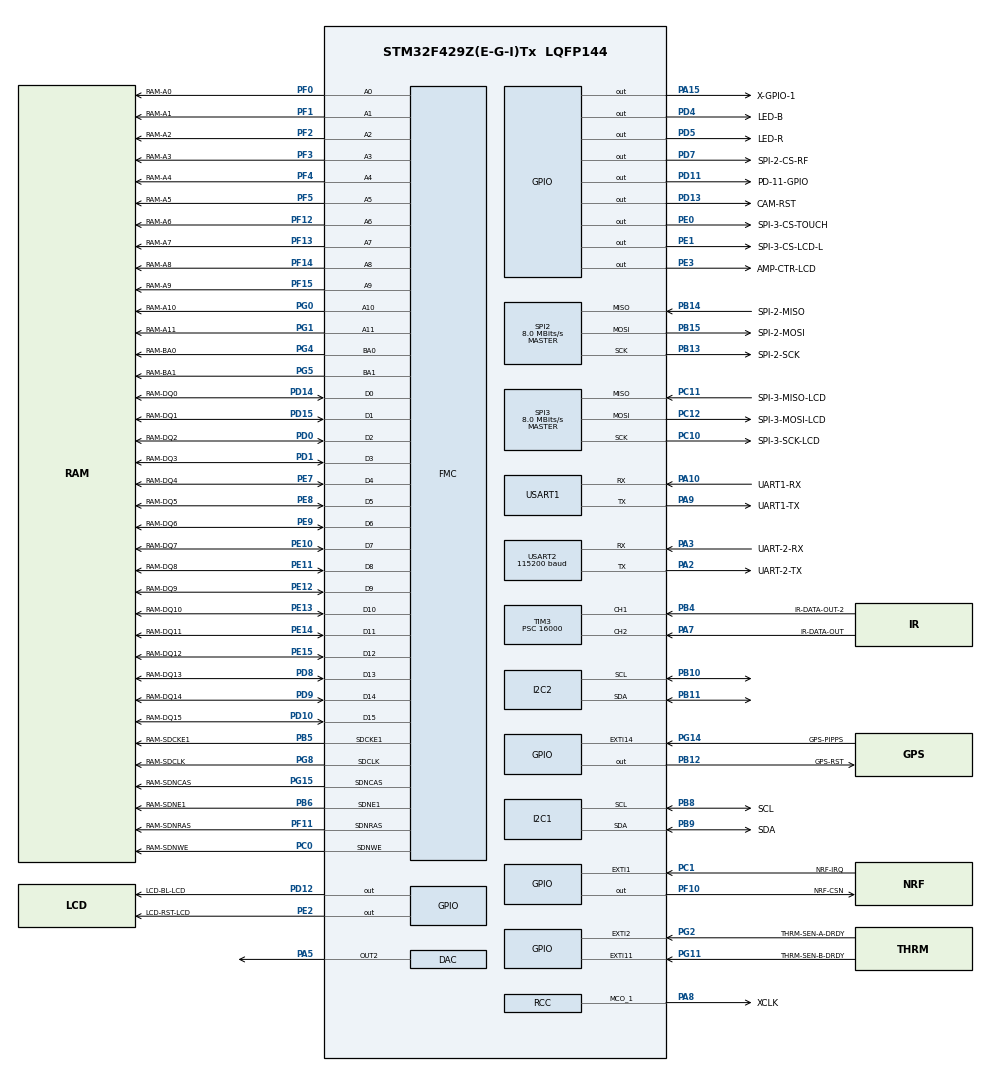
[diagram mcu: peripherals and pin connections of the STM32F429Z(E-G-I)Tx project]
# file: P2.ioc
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DAC.DAC_OutputBuffer2=DAC_OUTPUTBUFFER_ENABLE
DAC.DAC_Trigger2=DAC_TRIGGER_T6_TRGO
DAC.TriangleAmplitude2=DAC_TRIANGLEAMPLITUDE_4095
DAC.WaveGeneration2=TriangleWaveGeneration
Dma.I2C1_RX.2.Channel=DMA_CHANNEL_1
Dma.I2C1_RX.2.Direction=DMA_PERIPH_TO_MEMORY
Dma.I2C1_RX.2.FIFOMode=DMA_FIFOMODE_DISABLE
Dma.I2C1_RX.2.Instance=DMA1_Stream0
Dma.I2C1_RX.2.MemDataAlignment=DMA_MDATAALIGN_BYTE
Dma.I2C1_RX.2.MemInc=DMA_MINC_ENABLE
Dma.I2C1_RX.2.Mode=DMA_NORMAL
Dma.I2C1_RX.2.PeriphDataAlignment=DMA_PDATAALIGN_BYTE
Dma.I2C1_RX.2.PeriphInc=DMA_PINC_DISABLE
Dma.I2C1_RX.2.Priority=DMA_PRIORITY_LOW
Dma.Request0=SPI2_RX
Dma.Request1=SPI2_TX
Dma.Request2=I2C1_RX
Dma.Request3=USART2_RX
Dma.SPI2_RX.0.Channel=DMA_CHANNEL_0
Dma.SPI2_RX.0.Direction=DMA_PERIPH_TO_MEMORY
Dma.SPI2_RX.0.FIFOMode=DMA_FIFOMODE_DISABLE
Dma.SPI2_RX.0.Instance=DMA1_Stream3
Dma.SPI2_RX.0.MemDataAlignment=DMA_MDATAALIGN_BYTE
Dma.SPI2_RX.0.MemInc=DMA_MINC_ENABLE
Dma.SPI2_RX.0.Mode=DMA_NORMAL
Dma.SPI2_RX.0.PeriphDataAlignment=DMA_PDATAALIGN_BYTE
Dma.SPI2_RX.0.PeriphInc=DMA_PINC_DISABLE
Dma.SPI2_RX.0.Priority=DMA_PRIORITY_LOW
Dma.SPI2_TX.1.Channel=DMA_CHANNEL_0
Dma.SPI2_TX.1.Direction=DMA_MEMORY_TO_PERIPH
Dma.SPI2_TX.1.FIFOMode=DMA_FIFOMODE_DISABLE
Dma.SPI2_TX.1.Instance=DMA1_Stream4
Dma.SPI2_TX.1.MemDataAlignment=DMA_MDATAALIGN_BYTE
Dma.SPI2_TX.1.MemInc=DMA_MINC_ENABLE
Dma.SPI2_TX.1.Mode=DMA_NORMAL
Dma.SPI2_TX.1.PeriphDataAlignment=DMA_PDATAALIGN_BYTE
Dma.SPI2_TX.1.PeriphInc=DMA_PINC_DISABLE
Dma.SPI2_TX.1.Priority=DMA_PRIORITY_LOW
Dma.USART2_RX.3.Channel=DMA_CHANNEL_4
Dma.USART2_RX.3.Direction=DMA_PERIPH_TO_MEMORY
Dma.USART2_RX.3.FIFOMode=DMA_FIFOMODE_DISABLE
Dma.USART2_RX.3.Instance=DMA1_Stream5
Dma.USART2_RX.3.MemDataAlignment=DMA_MDATAALIGN_BYTE
Dma.USART2_RX.3.MemInc=DMA_MINC_ENABLE
Dma.USART2_RX.3.Mode=DMA_NORMAL
Dma.USART2_RX.3.PeriphDataAlignment=DMA_PDATAALIGN_BYTE
Dma.USART2_RX.3.PeriphInc=DMA_PINC_DISABLE
Dma.USART2_RX.3.Priority=DMA_PRIORITY_LOW
I2C1.NoStretchMode=I2C_NOSTRETCH_DISABLED
Mcu.Family=STM32F4
Mcu.Name=STM32F429Z(E-G-I)Tx
Mcu.Package=LQFP144
NVIC.DMA1_Stream0_IRQn=true\:0\:0\:false
NVIC.DMA1_Stream3_IRQn=true\:0\:0\:false
NVIC.DMA1_Stream4_IRQn=true\:0\:0\:false
NVIC.DMA1_Stream5_IRQn=true\:0\:0\:false
NVIC.EXTI15_10_IRQn=true\:0\:0\:false
NVIC.EXTI1_IRQn=true\:0\:0\:false
NVIC.EXTI2_IRQn=true\:0\:0\:false
NVIC.PriorityGroup=NVIC_PRIORITYGROUP_4
NVIC.RCC_IRQn=true\:0\:0\:false
NVIC.TIM3_IRQn=true\:0\:0\:false
NVIC.USART1_IRQn=true\:0\:0\:false
PA10.GPIO_Label=UART1-RX
PA10.Mode=Asynchronous
PA10.Signal=USART1_RX
PA13.Mode=Serial-Wire
PA13.Signal=SYS_JTMS-SWDIO
PA14.Mode=Serial-Wire
PA14.Signal=SYS_JTCK-SWCLK
PA15.GPIO_Label=X-GPIO-1
PA15.GPIO_PuPd=GPIO_PULLDOWN
PA15.Signal=GPIO_Output
PA2.GPIO_Label=UART-2-TX
PA2.GPIO_Speed=GPIO_SPEED_LOW
PA2.Mode=Asynchronous
PA2.Signal=USART2_TX
PA3.GPIO_Label=UART-2-RX
PA3.GPIO_Speed=GPIO_SPEED_LOW
PA3.Mode=Asynchronous
PA3.Signal=USART2_RX
PA5.Signal=COMP_DAC2_group
PA7.GPIO_Label=IR-DATA-OUT
PA7.Signal=S_TIM3_CH2
PA8.GPIO_Label=XCLK
PA8.GPIO_PuPd=GPIO_NOPULL
PA8.GPIO_Speed=GPIO_SPEED_FAST
PA8.Mode=Clock-out-1
PA8.Signal=RCC_MCO_1
PA9.GPIO_Label=UART1-TX
PA9.Mode=Asynchronous
PA9.Signal=USART1_TX
PB10.GPIO_PuPdOD=GPIO_NOPULL
PB10.GPIO_Speed=GPIO_SPEED_FAST
PB10.Mode=I2C
PB10.Signal=I2C2_SCL
PB11.GPIO_PuPdOD=GPIO_NOPULL
PB11.GPIO_Speed=GPIO_SPEED_FAST
PB11.Mode=I2C
PB11.Signal=I2C2_SDA
PB12.GPIO_Label=GPS-RST
PB12.Signal=GPIO_Output
PB13.GPIO_Label=SPI-2-SCK
PB13.Mode=Full_Duplex_Master
PB13.Signal=SPI2_SCK
PB14.GPIO_Label=SPI-2-MISO
PB14.Mode=Full_Duplex_Master
PB14.Signal=SPI2_MISO
PB15.GPIO_Label=SPI-2-MOSI
PB15.Mode=Full_Duplex_Master
PB15.Signal=SPI2_MOSI
PB4.GPIO_Label=IR-DATA-OUT-2
PB4.Signal=S_TIM3_CH1
PB5.GPIO_Label=RAM-SDCKE1
PB5.Mode=SdramChipSelect2_1
PB5.Signal=FMC_SDCKE1
PB6.GPIO_Label=RAM-SDNE1
PB6.Mode=SdramChipSelect2_1
PB6.Signal=FMC_SDNE1
PB8.GPIO_Label=SCL
PB8.GPIO_PuPdOD=GPIO_PULLUP
PB8.GPIO_Speed=GPIO_SPEED_MEDIUM
PB8.Mode=I2C
PB8.Signal=I2C1_SCL
PB9.GPIO_Label=SDA
PB9.GPIO_PuPdOD=GPIO_PULLUP
PB9.GPIO_Speed=GPIO_SPEED_MEDIUM
PB9.Mode=I2C
PB9.Signal=I2C1_SDA
PC0.GPIO_Label=RAM-SDNWE
PC0.Signal=FMC_SDNWE
PC1.GPIO_Label=NRF-IRQ
PC1.GPIO_ModeDefaultEXTI=GPIO_MODE_IT_FALLING
PC1.Signal=GPXTI1
PC10.GPIO_Label=SPI-3-SCK-LCD
PC10.GPIO_Speed=GPIO_SPEED_MEDIUM
PC10.Mode=Full_Duplex_Master
PC10.Signal=SPI3_SCK
PC11.GPIO_Label=SPI-3-MISO-LCD
PC11.GPIO_Speed=GPIO_SPEED_MEDIUM
PC11.Mode=Full_Duplex_Master
PC11.Signal=SPI3_MISO
PC12.GPIO_Label=SPI-3-MOSI-LCD
PC12.GPIO_Speed=GPIO_SPEED_MEDIUM
PC12.Mode=Full_Duplex_Master
PC12.Signal=SPI3_MOSI
PC14/OSC32_IN.Mode=LSE-External-Oscillator
PC14/OSC32_IN.Signal=RCC_OSC32_IN
PC15/OSC32_OUT.Mode=LSE-External-Oscillator
PC15/OSC32_OUT.Signal=RCC_OSC32_OUT
PD0.GPIO_Label=RAM-DQ2
PD0.Signal=FMC_D2_DA2
PD1.GPIO_Label=RAM-DQ3
PD1.Signal=FMC_D3_DA3
PD10.GPIO_Label=RAM-DQ15
PD10.Signal=FMC_D15_DA15
PD11.GPIO_Label=PD-11-GPIO
PD11.Signal=GPIO_Output
PD12.GPIO_Label=LCD-BL-LCD
PD12.Signal=GPIO_Output
PD13.GPIO_Label=CAM-RST
PD13.GPIO_PuPd=GPIO_PULLDOWN
PD13.GPIO_Speed=GPIO_SPEED_LOW
PD13.Signal=GPIO_Output
PD14.GPIO_Label=RAM-DQ0
PD14.Signal=FMC_D0_DA0
PD15.GPIO_Label=RAM-DQ1
PD15.Signal=FMC_D1_DA1
PD4.GPIO_Label=LED-B
PD4.Signal=GPIO_Output
PD5.GPIO_Label=LED-R
PD5.Signal=GPIO_Output
PD7.GPIO_Label=SPI-2-CS-RF
PD7.Signal=GPIO_Output
PD8.GPIO_Label=RAM-DQ13
PD8.Signal=FMC_D13_DA13
PD9.GPIO_Label=RAM-DQ14
PD9.Signal=FMC_D14_DA14
PE0.GPIO_Label=SPI-3-CS-TOUCH
PE0.GPIO_ModeDefaultOutputPP=GPIO_MODE_OUTPUT_PP
PE0.GPIO_PuPd=GPIO_NOPULL
PE0.Signal=GPIO_Output
PE1.GPIO_Label=SPI-3-CS-LCD-L
PE1.GPIO_ModeDefaultOutputPP=GPIO_MODE_OUTPUT_PP
PE1.GPIO_PuPd=GPIO_NOPULL
PE1.GPIO_Speed=GPIO_SPEED_LOW
PE1.Signal=GPIO_Output
PE10.GPIO_Label=RAM-DQ7
PE10.Signal=FMC_D7_DA7
PE11.GPIO_Label=RAM-DQ8
PE11.Signal=FMC_D8_DA8
PE12.GPIO_Label=RAM-DQ9
PE12.Signal=FMC_D9_DA9
PE13.GPIO_Label=RAM-DQ10
PE13.Signal=FMC_D10_DA10
PE14.GPIO_Label=RAM-DQ11
PE14.Signal=FMC_D11_DA11
PE15.GPIO_Label=RAM-DQ12
PE15.Signal=FMC_D12_DA12
PE2.GPIO_Label=LCD-RST-LCD
PE2.GPIO_ModeDefaultOutputPP=GPIO_MODE_OUTPUT_PP
PE2.GPIO_PuPd=GPIO_NOPULL
PE2.Signal=GPIO_Output
PE3.GPIO_Label=AMP-CTR-LCD
PE3.GPIO_ModeDefaultOutputPP=GPIO_MODE_OUTPUT_OD
PE3.GPIO_PuPd=GPIO_NOPULL
PE3.Signal=GPIO_Output
PE7.GPIO_Label=RAM-DQ4
PE7.Signal=FMC_D4_DA4
PE8.GPIO_Label=RAM-DQ5
PE8.Signal=FMC_D5_DA5
PE9.GPIO_Label=RAM-DQ6
PE9.Signal=FMC_D6_DA6
PF0.GPIO_Label=RAM-A0
PF0.Signal=FMC_A0
PF1.GPIO_Label=RAM-A1
PF1.Signal=FMC_A1
PF10.GPIO_Label=NRF-CSN
PF10.GPIO_ModeDefaultOutputPP=GPIO_MODE_OUTPUT_PP
PF10.GPIO_PuPd=GPIO_NOPULL
PF10.Signal=GPIO_Output
PF11.GPIO_Label=RAM-SDNRAS
PF11.Signal=FMC_SDNRAS
PF12.GPIO_Label=RAM-A6
PF12.Signal=FMC_A6
PF13.GPIO_Label=RAM-A7
PF13.Signal=FMC_A7
PF14.GPIO_Label=RAM-A8
PF14.Signal=FMC_A8
PF15.GPIO_Label=RAM-A9
PF15.Signal=FMC_A9
PF2.GPIO_Label=RAM-A2
PF2.Signal=FMC_A2
PF3.GPIO_Label=RAM-A3
PF3.Signal=FMC_A3
PF4.GPIO_Label=RAM-A4
PF4.Signal=FMC_A4
PF5.GPIO_Label=RAM-A5
PF5.Signal=FMC_A5
PG0.GPIO_Label=RAM-A10
PG0.Signal=FMC_A10
PG1.GPIO_Label=RAM-A11
PG1.Signal=FMC_A11
PG11.GPIO_Label=THRM-SEN-B-DRDY
PG11.GPIO_ModeDefaultEXTI=GPIO_MODE_IT_RISING
PG11.GPIO_PuPd=GPIO_NOPULL
PG11.Signal=GPXTI11
PG14.GPIO_Label=GPS-PIPPS
PG14.GPIO_PuPd=GPIO_NOPULL
PG14.Signal=GPXTI14
PG15.GPIO_Label=RAM-SDNCAS
PG15.Signal=FMC_SDNCAS
PG2.GPIO_Label=THRM-SEN-A-DRDY
PG2.GPIO_ModeDefaultEXTI=GPIO_MODE_IT_RISING
PG2.GPIO_PuPd=GPIO_NOPULL
PG2.Signal=GPXTI2
PG4.GPIO_Label=RAM-BA0
PG4.Signal=FMC_A14_BA0
PG5.GPIO_Label=RAM-BA1
PG5.Signal=FMC_A15_BA1
PG8.GPIO_Label=RAM-SDCLK
PG8.Signal=FMC_SDCLK
PH0/OSC_IN.Mode=HSE-External-Oscillator
PH0/OSC_IN.Signal=RCC_OSC_IN
PH1/OSC_OUT.Mode=HSE-External-Oscillator
PH1/OSC_OUT.Signal=RCC_OSC_OUT
ProjectManager.TargetToolchain=MDK-ARM V5
RCC.48MHZClocksFreq_Value=16000000
RCC.AHBFreq_Value=16000000
RCC.APB1Freq_Value=16000000
RCC.APB1TimFreq_Value=16000000
RCC.APB2Freq_Value=16000000
RCC.APB2TimFreq_Value=16000000
RCC.CortexFreq_Value=16000000
RCC.HCLKFreq_Value=16000000
RCC.HSE_VALUE=25000000
RCC.HSICalibrationValue=0
RCC.HSI_VALUE=16000000
RCC.PLLM=59
RCC.PLLN=236
RCC.RCC_TIM_PRescaler_Selection=RCC_TIMPRES_DESACTIVATED
RCC.SYSCLKFreq_VALUE=16000000
RCC.VCOOutputFreq_Value=64000000
SH.COMP_DAC2_group.0=DAC_OUT2,DAC_OUT2
SH.FMC_A0.0=FMC_A0,12b-sda1
SH.FMC_A1.0=FMC_A1,12b-sda1
SH.FMC_A10.0=FMC_A10,12b-sda1
SH.FMC_A11.0=FMC_A11,12b-sda1
SH.FMC_A14_BA0.0=FMC_BA0,FourSdramBanks1
SH.FMC_A15_BA1.0=FMC_BA1,FourSdramBanks1
SH.FMC_A2.0=FMC_A2,12b-sda1
SH.FMC_A3.0=FMC_A3,12b-sda1
SH.FMC_A4.0=FMC_A4,12b-sda1
SH.FMC_A5.0=FMC_A5,12b-sda1
SH.FMC_A6.0=FMC_A6,12b-sda1
SH.FMC_A7.0=FMC_A7,12b-sda1
SH.FMC_A8.0=FMC_A8,12b-sda1
SH.FMC_A9.0=FMC_A9,12b-sda1
SH.FMC_D0_DA0.0=FMC_D0,sd-16b-d1
SH.FMC_D10_DA10.0=FMC_D10,sd-16b-d1
SH.FMC_D11_DA11.0=FMC_D11,sd-16b-d1
SH.FMC_D12_DA12.0=FMC_D12,sd-16b-d1
SH.FMC_D13_DA13.0=FMC_D13,sd-16b-d1
SH.FMC_D14_DA14.0=FMC_D14,sd-16b-d1
SH.FMC_D15_DA15.0=FMC_D15,sd-16b-d1
SH.FMC_D1_DA1.0=FMC_D1,sd-16b-d1
SH.FMC_D2_DA2.0=FMC_D2,sd-16b-d1
SH.FMC_D3_DA3.0=FMC_D3,sd-16b-d1
SH.FMC_D4_DA4.0=FMC_D4,sd-16b-d1
SH.FMC_D5_DA5.0=FMC_D5,sd-16b-d1
SH.FMC_D6_DA6.0=FMC_D6,sd-16b-d1
SH.FMC_D7_DA7.0=FMC_D7,sd-16b-d1
SH.FMC_D8_DA8.0=FMC_D8,sd-16b-d1
SH.FMC_D9_DA9.0=FMC_D9,sd-16b-d1
SH.FMC_SDCLK.0=FMC_SDCLK,12b-sda1
SH.FMC_SDNCAS.0=FMC_SDNCAS,12b-sda1
SH.FMC_SDNRAS.0=FMC_SDNRAS,12b-sda1
SH.FMC_SDNWE.0=FMC_SDNWE,12b-sda1
SH.S_TIM3_CH1.0=TIM3_CH1,Input_Capture1_from_TI1
SH.S_TIM3_CH1.1=TIM3_CH1,TriggerSource_TI1FP1
SH.S_TIM3_CH2.0=TIM3_CH2,Input_Capture2_from_TI2
SPI2.CalculateBaudRate=8.0 MBits/s
SPI2.Mode=SPI_MODE_MASTER
SPI3.BaudRatePrescaler=SPI_BAUDRATEPRESCALER_2
SPI3.CLKPolarity=SPI_POLARITY_LOW
SPI3.CalculateBaudRate=8.0 MBits/s
SPI3.DataSize=SPI_DATASIZE_8BIT
SPI3.Mode=SPI_MODE_MASTER
TIM3.Channel-Input_Capture2_from_TI2=TIM_CHANNEL_2
TIM3.ICPolarity_CH1=TIM_INPUTCHANNELPOLARITY_RISING
TIM3.Period=19
TIM3.Prescaler=16000
TIM3.TIM_MasterOutputTrigger=TIM_TRGO_UPDATE
TIM6.Period=5
TIM6.Prescaler=0
TIM6.TIM_MasterOutputTrigger=TIM_TRGO_UPDATE
USART2.BaudRate=115200
USART2.WordLength=UART_WORDLENGTH_8B
VP_TIM3_VS_ClockSourceINT.Mode=Internal
VP_TIM3_VS_ControllerModeReset.Mode=Reset Mode
VP_TIM6_VS_ClockSourceINT.Mode=Enable_Timer
board=P2

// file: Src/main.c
/**
  ******************************************************************************
  * File Name          : main.c
  * Description        : Main program body
  ******************************************************************************
  *
  * COPYRIGHT(c) 2015 STMicroelectronics
  *
  * Redistribution and use in source and binary forms, with or without modification,
  * are permitted provided that the following conditions are met:
  *   1. Redistributions of source code must retain the above copyright notice,
  *      this list of conditions and the following disclaimer.
  *   2. Redistributions in binary form must reproduce the above copyright notice,
  *      this list of conditions and the following disclaimer in the documentation
  *      and/or other materials provided with the distribution.
  *   3. Neither the name of STMicroelectronics nor the names of its contributors
  *      may be used to endorse or promote products derived from this software
  *      without specific prior written permission.
  *
  * THIS SOFTWARE IS PROVIDED BY THE COPYRIGHT HOLDERS AND CONTRIBUTORS "AS IS"
  * AND ANY EXPRESS OR IMPLIED WARRANTIES, INCLUDING, BUT NOT LIMITED TO, THE
  * IMPLIED WARRANTIES OF MERCHANTABILITY AND FITNESS FOR A PARTICULAR PURPOSE ARE
  * DISCLAIMED. IN NO EVENT SHALL THE COPYRIGHT HOLDER OR CONTRIBUTORS BE LIABLE
  * FOR ANY DIRECT, INDIRECT, INCIDENTAL, SPECIAL, EXEMPLARY, OR CONSEQUENTIAL
  * DAMAGES (INCLUDING, BUT NOT LIMITED TO, PROCUREMENT OF SUBSTITUTE GOODS OR
  * SERVICES; LOSS OF USE, DATA, OR PROFITS; OR BUSINESS INTERRUPTION) HOWEVER
  * CAUSED AND ON ANY THEORY OF LIABILITY, WHETHER IN CONTRACT, STRICT LIABILITY,
  * OR TORT (INCLUDING NEGLIGENCE OR OTHERWISE) ARISING IN ANY WAY OUT OF THE USE
  * OF THIS SOFTWARE, EVEN IF ADVISED OF THE POSSIBILITY OF SUCH DAMAGE.
  *
  ******************************************************************************
  */
#include "stm32f4xx_hal.h"

/* USER CODE BEGIN Includes */
//#include "stdio.h"
//#include "3_I2C1_TMP006.h"
//#include "4_5_I2C1_Si7020.h"
//#include "8_UART1.h"
//#include "10_SPI2_NRF24L01.h"
//#include "12_FMC_SDRAM.h"
#include "15_lights.h"
//#include "19_UART2_GPS.h"
//#include "18_I2C1_MPU9150.h"
//#include "17_DAC_Audio.h"
//#include "14_IR_Sensor.h"
struct __FILE { int handle; };
FILE __stdout;
FILE __stdin;
int fputc(int c, FILE *f)
{
ITM_SendChar(c);
return (c);
}

//#include "SPI3_LCD.h"
//#include "7_I2C2_OV7670.h"

/* USER CODE END Includes */

DAC_HandleTypeDef hdac;

I2C_HandleTypeDef hi2c1;
I2C_HandleTypeDef hi2c2;
DMA_HandleTypeDef hdma_i2c1_rx;

SPI_HandleTypeDef hspi2;
SPI_HandleTypeDef hspi3;
DMA_HandleTypeDef hdma_spi2_rx;
DMA_HandleTypeDef hdma_spi2_tx;

TIM_HandleTypeDef htim3;
TIM_HandleTypeDef htim6;

UART_HandleTypeDef huart1;
UART_HandleTypeDef huart2;
DMA_HandleTypeDef hdma_usart2_rx;

SDRAM_HandleTypeDef hsdram1;

/* USER CODE BEGIN PV */
/* Private variables ---------------------------------------------------------*/

uint16_t  si_eid1 = 0;
uint16_t  si_eid2 = 0;
uint8_t  si_firm = 0;
uint8_t  si_heat = 0;
float    si_hum = 0;
float    si_temp = 0 ;
float    si_temp_r = 0 ;

uint8_t cam_pid_msb = 0;
uint8_t cam_pid_lsb = 0;
uint8_t cam_gain = 0;
uint8_t cam_blue = 0;
uint8_t cam_red = 0;

uint16_t tmp006_dev_id1 = 0;
uint16_t tmp006_man_id1 = 0;
uint16_t tmp006_temp1 = 0;
uint16_t tmp006_sens1 = 0;

uint16_t tmp006_dev_id2 = 0;
uint16_t tmp006_man_id2 = 0;
uint16_t tmp006_temp2 = 0;
uint16_t tmp006_sens2 = 0;

uint8_t nrf_config = 0;
uint8_t nrf_en_aa = 0;
uint8_t nrf_en_rxaddr = 0;
uint8_t nrf_setup_aw = 0;
uint8_t nrf_setup_retr = 0;
uint8_t nrf_rf_ch = 0;
uint8_t nrf_rf_setup = 0;
uint8_t nrf_status = 0;
uint8_t nrf_observe_tx  = 0;

uint8_t gps_sid = 0;

uint64_t lcd_man_id =0;
uint64_t lcd_dri_ver = 0;
uint64_t lcd_dri_id = 0;
uint64_t lcd_mem_acc_con = 0;
uint64_t lcd_disp_pow_mod = 0;
uint64_t lcd_rddsdr = 0;
uint64_t lcd_disp_stat = 0;
uint64_t lcd_mem_read = 0;

uint8_t   acc_smprt_div = 0;
uint8_t   acc_config = 0;
uint8_t   acc_gyro_config = 0;
uint16_t  ACCEL_XOUT_H = 0;
uint8_t   ACCEL_XOUT_L = 0;
uint16_t  ACCEL_YOUT_H = 0;
uint8_t   ACCEL_YOUT_L = 0;
uint16_t  ACCEL_ZOUT_H = 0;
uint8_t   ACCEL_ZOUT_L = 0;
uint16_t  GYRO_XOUT_H  = 0;
uint8_t   GYRO_XOUT_L  = 0;
uint16_t  GYRO_YOUT_H  = 0;
uint8_t   GYRO_YOUT_L  = 0;
uint16_t  GYRO_ZOUT_H  = 0;
uint8_t   GYRO_ZOUT_L  = 0;

uint8_t  acc_who_am_i = 0;
uint8_t  acc_pwr_mgmt_1;
uint8_t  acc_pwr_mgmt_2;

uint32_t DAC_Out = 0 ;

extern uint32_t sd_rb;       // READ BUFFER FOR SD CARD

/* USER CODE END PV */

void SystemClock_Config(void);
static void MX_GPIO_Init(void);
static void MX_DMA_Init(void);
static void MX_DAC_Init(void);
static void MX_FMC_Init(void);
static void MX_I2C1_Init(void);
static void MX_I2C2_Init(void);
static void MX_SPI2_Init(void);
static void MX_SPI3_Init(void);
static void MX_TIM3_Init(void);
static void MX_TIM6_Init(void);
static void MX_USART1_UART_Init(void);
static void MX_USART2_UART_Init(void);

/* USER CODE BEGIN PFP */
/* Private function prototypes -----------------------------------------------*/

/* USER CODE END PFP */

int main(void)
{

  /* MCU Configuration----------------------------------------------------------*/

  /* Reset of all peripherals, Initializes the Flash interface and the Systick. */
  HAL_Init();

  /* Configure the system clock */
  SystemClock_Config();

  /* Initialize all configured peripherals */
  MX_GPIO_Init();
  MX_DMA_Init();
  MX_DAC_Init();
  MX_FMC_Init();
  MX_I2C1_Init();
  MX_I2C2_Init();
  MX_SPI2_Init();
  MX_SPI3_Init();
  MX_TIM3_Init();
  MX_TIM6_Init();
  MX_USART1_UART_Init();
  MX_USART2_UART_Init();

  /* USER CODE BEGIN 2 */

	 // TMP006 FUNCTIONS

	/***********************************/

	tmp006_man_id1 = r_man_id1();
	tmp006_dev_id1 = r_dev_id1();
	tmp006_man_id2 = r_man_id2();
	tmp006_dev_id2 = r_dev_id2();
	tmp006_temp1 = r_temp1();
	tmp006_sens1 = r_sens1();
  tmp006_temp2 = r_temp2();
	tmp006_sens2 = r_sens2();

	/**************************************/

/*************** NRF2401L  FUNCTIONS *****************

w_config(0x04);
nrf_config     = r_config();    // READ CONFIGURATION REGISTER OF NRF24L01
nrf_en_aa      = r_en_aa();     // READ ENABLE AUTO ACKNOWLEDGEMENT REGISTER OF NRF24L01
nrf_en_rxaddr  = r_en_rxaddr(); // READ ENABLED RX ADDRESSES OF NRF24L01
nrf_setup_aw   = r_setup_aw();  // READ SETUP OF ADDRESS WIDTHS OF NRF24L01
nrf_setup_retr = r_setup_retr();// READ SETUP OF AUTOMATIC RETRANSMISSION REGISTER OF NRF24L01
nrf_rf_ch      = r_rf_ch();     // READ RF CHANNEL REGISTER OF NRF24L01
nrf_rf_setup   = r_rf_setup() ; // READ RF SETUP REGISTER OF NRF24L01
nrf_status     = r_status();    // READ STATUS REGISTER OF NRF24L01
nrf_observe_tx = r_observe_tx();// READ TRANSMIT OBSERVE REGISTER OF NRF24L01
r_rpd        ();                // READ RECEIVED POWER DETECT REGISTER OF NRF24L01
r_rx_addr_p0 ();                // READ RECEIVED DATA PIPE 0
r_rx_addr_p1 ();                // READ RECEIVED DATA PIPE 1
r_rx_addr_p2 ();                // READ RECEIVED DATA PIPE 2
r_rx_addr_p3 ();                // READ RECEIVED DATA PIPE 3
r_rx_addr_p4 ();                // READ RECEIVED DATA PIPE 4
r_rx_addr_p5 ();                // READ RECEIVED DATA PIPE 5
r_tx_addr    ();                // READ RECEIVED TRANSMIT REGISTER OF NRF24L01
r_rx_pw_p0   ();                // READ NUMBER OF BYTES IN RX PAYLOAD IN DATA PIPE 0 OF NRF24L01
r_rx_pw_p1   ();                // READ NUMBER OF BYTES IN RX PAYLOAD IN DATA PIPE 1 OF NRF24L01
r_rx_pw_p2   ();                // READ NUMBER OF BYTES IN RX PAYLOAD IN DATA PIPE 2 OF NRF24L01
r_rx_pw_p3   ();                // READ NUMBER OF BYTES IN RX PAYLOAD IN DATA PIPE 3 OF NRF24L01
r_rx_pw_p4   ();                // READ NUMBER OF BYTES IN RX PAYLOAD IN DATA PIPE 4 OF NRF24L01
r_rx_pw_p5   ();                // READ NUMBER OF BYTES IN RX PAYLOAD IN DATA PIPE 5 OF NRF24L01

************************************************************************************************/

/********** SDRAM FUNCTIONS******************

uint32_t data[] = {0x0A,0x0B,0x0C,0x0D};
write_sd_mem((uint32_t*)data);
read_sd_mem();

*******************************************/

/*************UART SERIAL CAMERA INTERFACE*******************

uint8_t buff[] ="hello";
uart1_send((uint8_t*)buff);

**********************************************************/

/*************ACCELROMETER/GYROSCOPE FUNCTIONS***********

mpu_stat();
acc_who_am_i     =  r_who_am_i();
slp_mod_of();
w_smprt_div(0x18);
acc_smprt_div    =  r_smprt_div();
w_config(0x18);
acc_config       =  r_config();
w_gyro_config(0x18);
acc_gyro_config  =  r_gyro_config();
acc_pwr_mgmt_1   =  r_pwr_mgmt_1();
acc_pwr_mgmt_2   =  r_pwr_mgmt_2();
ACCEL_XOUT_H     =  r_MPU9150_ACCEL_XOUT_H();
ACCEL_XOUT_L     =  r_MPU9150_ACCEL_XOUT_L();
ACCEL_YOUT_H     =  r_MPU9150_ACCEL_YOUT_H();
ACCEL_YOUT_L     =  r_MPU9150_ACCEL_YOUT_L();
ACCEL_ZOUT_H     =  r_MPU9150_ACCEL_ZOUT_H();
ACCEL_ZOUT_L     =  r_MPU9150_ACCEL_ZOUT_L();
GYRO_XOUT_H      =  r_MPU9150_GYRO_XOUT_H();
GYRO_XOUT_L      =  r_MPU9150_GYRO_XOUT_L();
GYRO_YOUT_H      =  r_MPU9150_GYRO_YOUT_H();
GYRO_YOUT_L      =  r_MPU9150_GYRO_YOUT_L();
GYRO_ZOUT_H      =  r_MPU9150_GYRO_ZOUT_H();
GYRO_ZOUT_L      =  r_MPU9150_GYRO_ZOUT_L();

*********************************************************/

/******************LCD FUNCTIONS****************************
Lcd_Ton();                              //LCD TOUCH CONTROLLER CSX = 1
Lcd_on();
Lcd_Set();
Lcd_Bl_On();
lcd_man_id        =    Lcd_man_id_r();
lcd_mem_acc_con   =    Lcd_mem_acc_con_r();
Lcd_mem_acc_con_w(0x0020);
lcd_mem_acc_con   =    Lcd_mem_acc_con_r();
//lcd_dri_ver       =    Lcd_dri_ver_r();
//lcd_dri_id        =    Lcd_dri_id_r();
Lcd_normal_mode_on();
lcd_dri_ver       =    Lcd_dri_ver_r();
lcd_dri_id        =    Lcd_dri_id_r();
lcd_disp_stat     =    Lcd_disp_stat_r();
lcd_mem_acc_con   =    Lcd_mem_acc_con_r();
lcd_disp_pow_mod  =    Lcd_disp_pow_mod_r();
lcd_rddsdr        =    Lcd_rddsdr_r();
Lcd_column_addr_w(0x01,0x00,0x02,0x00);
Lcd_page_addr_w(0x01,0x00,0x02,0x00);
Lcd_mem_w(0x02);

lcd_mem_read=Lcd_mem_r();
***************************************************************/

/************** OV7670 FUNCTIONS***************

Cam_Pwup();
Cam_Set();
Cam_Stat();
cam_pid_msb = R_Cam_PID();
//cam_pid_lsb = Cam_Ver();
//cam_pid_msb = r_Cam_Pid();
//set_OV7670reg();
//cam_pid_msb = r_Cam_Pid();
**********************************************/

printf("  PROJECT : LAWN MOWING ROBOT \n ");
all_lights_off();

	//  SI7020 FUNCTIONS

	/***********************************
	//rst_si7020();
	//rst_si7020();
 	//si_stat();
	si_firm     =    r_firm_v();    // Command For Reading Firwamre Version
 	si_eid1     =    r_eid1();      // Command For Reading 1st Electronic ID Second Byte
	si_eid2     =    r_eid2();      // Command For Reading 2nd Electronic ID Second Byte
	//si_heat     =    r_heat();      // Command For Reading Heater Register
  si_hum      =    r_hum1();      // Command To Measure Relative Humidity ,Hold Master Mode
  si_temp     =    r_temp11();    // Command To Measure Temperature  , Hold Master Mode
	si_temp_r   =    r_temp33();    // Command For Reading Temperature , From Previous RH Measurement

  **************************************/

/*************UART GPS FUNCTIONS*************************

//GPS_RST();
//HAL_Delay(1000);
//GPS_SET();
//HAL_Delay(10000);
GPS_Config_Out_NMEA();
GPS_Config_Out_BINARY();
GPS_Config_Pos_Update_Rate();
GPS_Config_Bin_Meas_Data_Out();
GPS_QRCNS();
GPS_QBDOS();
GPS_QSID();                     // GPS : QUERY SOFTWARE VERSION ID
//GPS_Query_Pos_Update_Rate();
GPS_RCV_DATA();

**********************************************************/

/*************DAC FUNCTIONS**********************

Amp_En();
DAC_Start();

***************************************/

/**********IR Sensor Functions********

Start_Timer3_IR1();
Start_Timer3_IR2();

*****************************/

  /* USER CODE END 2 */

  /* Infinite loop */
  while (1)
  {

  }

}

/** System Clock Configuration
*/
void SystemClock_Config(void)
{

  RCC_OscInitTypeDef RCC_OscInitStruct;

  __PWR_CLK_ENABLE();

  __HAL_PWR_VOLTAGESCALING_CONFIG(PWR_REGULATOR_VOLTAGE_SCALE3);

  RCC_OscInitStruct.OscillatorType = RCC_OSCILLATORTYPE_HSI;
  RCC_OscInitStruct.HSIState = RCC_HSI_ON;
  RCC_OscInitStruct.HSICalibrationValue = 0;
  RCC_OscInitStruct.PLL.PLLState = RCC_PLL_NONE;
  HAL_RCC_OscConfig(&RCC_OscInitStruct);

  HAL_RCC_MCOConfig(RCC_MCO1, RCC_MCO1SOURCE_HSI, RCC_MCODIV_1);

  HAL_SYSTICK_Config(HAL_RCC_GetHCLKFreq()/1000);

  HAL_SYSTICK_CLKSourceConfig(SYSTICK_CLKSOURCE_HCLK);

  /* SysTick_IRQn interrupt configuration */
  HAL_NVIC_SetPriority(SysTick_IRQn, 0, 0);
}

/* DAC init function */
void MX_DAC_Init(void)
{

  DAC_ChannelConfTypeDef sConfig;

    /**DAC Initialization
    */
  hdac.Instance = DAC;
  HAL_DAC_Init(&hdac);

    /**DAC channel OUT2 config
    */
  sConfig.DAC_Trigger = DAC_TRIGGER_T6_TRGO;
  sConfig.DAC_OutputBuffer = DAC_OUTPUTBUFFER_ENABLE;
  HAL_DAC_ConfigChannel(&hdac, &sConfig, DAC_CHANNEL_2);

    /**Configure Triangle wave generation on DAC OUT2
    */
  HAL_DACEx_TriangleWaveGenerate(&hdac, DAC_CHANNEL_2, DAC_TRIANGLEAMPLITUDE_4095);

}

/* I2C1 init function */
void MX_I2C1_Init(void)
{

  hi2c1.Instance = I2C1;
  hi2c1.Init.ClockSpeed = 100000;
  hi2c1.Init.DutyCycle = I2C_DUTYCYCLE_2;
  hi2c1.Init.OwnAddress1 = 0;
  hi2c1.Init.AddressingMode = I2C_ADDRESSINGMODE_7BIT;
  hi2c1.Init.DualAddressMode = I2C_DUALADDRESS_DISABLED;
  hi2c1.Init.OwnAddress2 = 0;
  hi2c1.Init.GeneralCallMode = I2C_GENERALCALL_DISABLED;
  hi2c1.Init.NoStretchMode = I2C_NOSTRETCH_DISABLED;
  HAL_I2C_Init(&hi2c1);

}

/* I2C2 init function */
void MX_I2C2_Init(void)
{

  hi2c2.Instance = I2C2;
  hi2c2.Init.ClockSpeed = 100000;
  hi2c2.Init.DutyCycle = I2C_DUTYCYCLE_2;
  hi2c2.Init.OwnAddress1 = 0;
  hi2c2.Init.AddressingMode = I2C_ADDRESSINGMODE_7BIT;
  hi2c2.Init.DualAddressMode = I2C_DUALADDRESS_DISABLED;
  hi2c2.Init.OwnAddress2 = 0;
  hi2c2.Init.GeneralCallMode = I2C_GENERALCALL_DISABLED;
  hi2c2.Init.NoStretchMode = I2C_NOSTRETCH_DISABLED;
  HAL_I2C_Init(&hi2c2);

}

/* SPI2 init function */
void MX_SPI2_Init(void)
{

  hspi2.Instance = SPI2;
  hspi2.Init.Mode = SPI_MODE_MASTER;
  hspi2.Init.Direction = SPI_DIRECTION_2LINES;
  hspi2.Init.DataSize = SPI_DATASIZE_8BIT;
  hspi2.Init.CLKPolarity = SPI_POLARITY_LOW;
  hspi2.Init.CLKPhase = SPI_PHASE_1EDGE;
  hspi2.Init.NSS = SPI_NSS_SOFT;
  hspi2.Init.BaudRatePrescaler = SPI_BAUDRATEPRESCALER_2;
  hspi2.Init.FirstBit = SPI_FIRSTBIT_MSB;
  hspi2.Init.TIMode = SPI_TIMODE_DISABLED;
  hspi2.Init.CRCCalculation = SPI_CRCCALCULATION_DISABLED;
  hspi2.Init.CRCPolynomial = 10;
  HAL_SPI_Init(&hspi2);

}

/* SPI3 init function */
void MX_SPI3_Init(void)
{

  hspi3.Instance = SPI3;
  hspi3.Init.Mode = SPI_MODE_MASTER;
  hspi3.Init.Direction = SPI_DIRECTION_2LINES;
  hspi3.Init.DataSize = SPI_DATASIZE_8BIT;
  hspi3.Init.CLKPolarity = SPI_POLARITY_LOW;
  hspi3.Init.CLKPhase = SPI_PHASE_1EDGE;
  hspi3.Init.NSS = SPI_NSS_SOFT;
  hspi3.Init.BaudRatePrescaler = SPI_BAUDRATEPRESCALER_2;
  hspi3.Init.FirstBit = SPI_FIRSTBIT_MSB;
  hspi3.Init.TIMode = SPI_TIMODE_DISABLED;
  hspi3.Init.CRCCalculation = SPI_CRCCALCULATION_DISABLED;
  hspi3.Init.CRCPolynomial = 10;
  HAL_SPI_Init(&hspi3);

}

/* TIM3 init function */
void MX_TIM3_Init(void)
{

  TIM_ClockConfigTypeDef sClockSourceConfig;
  TIM_SlaveConfigTypeDef sSlaveConfig;
  TIM_MasterConfigTypeDef sMasterConfig;
  TIM_IC_InitTypeDef sConfigIC;

  htim3.Instance = TIM3;
  htim3.Init.Prescaler = 16000;
  htim3.Init.CounterMode = TIM_COUNTERMODE_UP;
  htim3.Init.Period = 19;
  htim3.Init.ClockDivision = TIM_CLOCKDIVISION_DIV1;
  HAL_TIM_Base_Init(&htim3);

  sClockSourceConfig.ClockSource = TIM_CLOCKSOURCE_INTERNAL;
  HAL_TIM_ConfigClockSource(&htim3, &sClockSourceConfig);

  HAL_TIM_IC_Init(&htim3);

  sSlaveConfig.SlaveMode = TIM_SLAVEMODE_RESET;
  sSlaveConfig.InputTrigger = TIM_TS_TI1FP1;
  sSlaveConfig.TriggerPolarity = TIM_INPUTCHANNELPOLARITY_RISING;
  sSlaveConfig.TriggerFilter = 0;
  HAL_TIM_SlaveConfigSynchronization(&htim3, &sSlaveConfig);

  sMasterConfig.MasterOutputTrigger = TIM_TRGO_UPDATE;
  sMasterConfig.MasterSlaveMode = TIM_MASTERSLAVEMODE_DISABLE;
  HAL_TIMEx_MasterConfigSynchronization(&htim3, &sMasterConfig);

  sConfigIC.ICPolarity = TIM_INPUTCHANNELPOLARITY_RISING;
  sConfigIC.ICSelection = TIM_ICSELECTION_DIRECTTI;
  sConfigIC.ICPrescaler = TIM_ICPSC_DIV1;
  sConfigIC.ICFilter = 0;
  HAL_TIM_IC_ConfigChannel(&htim3, &sConfigIC, TIM_CHANNEL_1);

  HAL_TIM_IC_ConfigChannel(&htim3, &sConfigIC, TIM_CHANNEL_2);

}

/* TIM6 init function */
void MX_TIM6_Init(void)
{

  TIM_MasterConfigTypeDef sMasterConfig;

  htim6.Instance = TIM6;
  htim6.Init.Prescaler = 0;
  htim6.Init.CounterMode = TIM_COUNTERMODE_UP;
  htim6.Init.Period = 5;
  HAL_TIM_Base_Init(&htim6);

  sMasterConfig.MasterOutputTrigger = TIM_TRGO_UPDATE;
  sMasterConfig.MasterSlaveMode = TIM_MASTERSLAVEMODE_DISABLE;
  HAL_TIMEx_MasterConfigSynchronization(&htim6, &sMasterConfig);

}

/* USART1 init function */
void MX_USART1_UART_Init(void)
{

  huart1.Instance = USART1;
  huart1.Init.BaudRate = 115200;
  huart1.Init.WordLength = UART_WORDLENGTH_8B;
  huart1.Init.StopBits = UART_STOPBITS_1;
  huart1.Init.Parity = UART_PARITY_NONE;
  huart1.Init.Mode = UART_MODE_TX_RX;
  huart1.Init.HwFlowCtl = UART_HWCONTROL_NONE;
  huart1.Init.OverSampling = UART_OVERSAMPLING_16;
  HAL_UART_Init(&huart1);

}

/* USART2 init function */
void MX_USART2_UART_Init(void)
{

  huart2.Instance = USART2;
  huart2.Init.BaudRate = 115200;
  huart2.Init.WordLength = UART_WORDLENGTH_8B;
  huart2.Init.StopBits = UART_STOPBITS_1;
  huart2.Init.Parity = UART_PARITY_NONE;
  huart2.Init.Mode = UART_MODE_TX_RX;
  huart2.Init.HwFlowCtl = UART_HWCONTROL_NONE;
  huart2.Init.OverSampling = UART_OVERSAMPLING_16;
  HAL_UART_Init(&huart2);

}

void MX_DMA_Init(void)
{
  /* DMA controller clock enable */
  __DMA1_CLK_ENABLE();

  /* DMA interrupt init */
  HAL_NVIC_SetPriority(DMA1_Stream0_IRQn, 0, 0);
  HAL_NVIC_EnableIRQ(DMA1_Stream0_IRQn);
  HAL_NVIC_SetPriority(DMA1_Stream3_IRQn, 0, 0);
  HAL_NVIC_EnableIRQ(DMA1_Stream3_IRQn);
  HAL_NVIC_SetPriority(DMA1_Stream4_IRQn, 0, 0);
  HAL_NVIC_EnableIRQ(DMA1_Stream4_IRQn);
  HAL_NVIC_SetPriority(DMA1_Stream5_IRQn, 0, 0);
  HAL_NVIC_EnableIRQ(DMA1_Stream5_IRQn);

}
/* FMC initialization function */
void MX_FMC_Init(void)
{
  FMC_SDRAM_TimingTypeDef SdramTiming;

  /** Perform the SDRAM1 memory initialization sequence
  */
  hsdram1.Instance = FMC_SDRAM_DEVICE;
  /* hsdram1.Init */
  hsdram1.Init.SDBank = FMC_SDRAM_BANK2;
  hsdram1.Init.ColumnBitsNumber = FMC_SDRAM_COLUMN_BITS_NUM_8;
  hsdram1.Init.RowBitsNumber = FMC_SDRAM_ROW_BITS_NUM_11;
  hsdram1.Init.MemoryDataWidth = FMC_SDRAM_MEM_BUS_WIDTH_16;
  hsdram1.Init.InternalBankNumber = FMC_SDRAM_INTERN_BANKS_NUM_4;
  hsdram1.Init.CASLatency = FMC_SDRAM_CAS_LATENCY_1;
  hsdram1.Init.WriteProtection = FMC_SDRAM_WRITE_PROTECTION_DISABLE;
  hsdram1.Init.SDClockPeriod = FMC_SDRAM_CLOCK_DISABLE;
  hsdram1.Init.ReadBurst = FMC_SDRAM_RBURST_DISABLE;
  hsdram1.Init.ReadPipeDelay = FMC_SDRAM_RPIPE_DELAY_0;
  /* SdramTiming */
  SdramTiming.LoadToActiveDelay = 16;
  SdramTiming.ExitSelfRefreshDelay = 16;
  SdramTiming.SelfRefreshTime = 16;
  SdramTiming.RowCycleDelay = 16;
  SdramTiming.WriteRecoveryTime = 16;
  SdramTiming.RPDelay = 16;
  SdramTiming.RCDDelay = 16;

  HAL_SDRAM_Init(&hsdram1, &SdramTiming);

}

/** Configure pins as
        * Analog
        * Input
        * Output
        * EVENT_OUT
        * EXTI
     PA8   ------> RCC_MCO_1
*/
void MX_GPIO_Init(void)
{

  GPIO_InitTypeDef GPIO_InitStruct;

  /* GPIO Ports Clock Enable */
  __GPIOE_CLK_ENABLE();
  __GPIOC_CLK_ENABLE();
  __GPIOF_CLK_ENABLE();
  __GPIOH_CLK_ENABLE();
  __GPIOA_CLK_ENABLE();
  __GPIOG_CLK_ENABLE();
  __GPIOB_CLK_ENABLE();
  __GPIOD_CLK_ENABLE();

  /*Configure GPIO pins : LCD_RST_LCD_Pin SPI_3_CS_TOUCH_Pin SPI_3_CS_LCD_L_Pin */
  GPIO_InitStruct.Pin = LCD_RST_LCD_Pin|SPI_3_CS_TOUCH_Pin|SPI_3_CS_LCD_L_Pin;
  GPIO_InitStruct.Mode = GPIO_MODE_OUTPUT_PP;
  GPIO_InitStruct.Pull = GPIO_NOPULL;
  GPIO_InitStruct.Speed = GPIO_SPEED_LOW;
  HAL_GPIO_Init(GPIOE, &GPIO_InitStruct);

  /*Configure GPIO pin : AMP_CTR_LCD_Pin */
  GPIO_InitStruct.Pin = AMP_CTR_LCD_Pin;
  GPIO_InitStruct.Mode = GPIO_MODE_OUTPUT_OD;
  GPIO_InitStruct.Pull = GPIO_NOPULL;
  GPIO_InitStruct.Speed = GPIO_SPEED_LOW;
  HAL_GPIO_Init(AMP_CTR_LCD_GPIO_Port, &GPIO_InitStruct);

  /*Configure GPIO pin : NRF_CSN_Pin */
  GPIO_InitStruct.Pin = NRF_CSN_Pin;
  GPIO_InitStruct.Mode = GPIO_MODE_OUTPUT_PP;
  GPIO_InitStruct.Pull = GPIO_NOPULL;
  GPIO_InitStruct.Speed = GPIO_SPEED_LOW;
  HAL_GPIO_Init(NRF_CSN_GPIO_Port, &GPIO_InitStruct);

  /*Configure GPIO pin : NRF_IRQ_Pin */
  GPIO_InitStruct.Pin = NRF_IRQ_Pin;
  GPIO_InitStruct.Mode = GPIO_MODE_IT_FALLING;
  GPIO_InitStruct.Pull = GPIO_NOPULL;
  HAL_GPIO_Init(NRF_IRQ_GPIO_Port, &GPIO_InitStruct);

  /*Configure GPIO pin : GPS_RST_Pin */
  GPIO_InitStruct.Pin = GPS_RST_Pin;
  GPIO_InitStruct.Mode = GPIO_MODE_OUTPUT_PP;
  GPIO_InitStruct.Pull = GPIO_NOPULL;
  GPIO_InitStruct.Speed = GPIO_SPEED_LOW;
  HAL_GPIO_Init(GPS_RST_GPIO_Port, &GPIO_InitStruct);

  /*Configure GPIO pins : PD_11_GPIO_Pin LCD_BL_LCD_Pin LED_B_Pin LED_R_Pin
                           SPI_2_CS_RF_Pin */
  GPIO_InitStruct.Pin = PD_11_GPIO_Pin|LCD_BL_LCD_Pin|LED_B_Pin|LED_R_Pin
                          |SPI_2_CS_RF_Pin;
  GPIO_InitStruct.Mode = GPIO_MODE_OUTPUT_PP;
  GPIO_InitStruct.Pull = GPIO_NOPULL;
  GPIO_InitStruct.Speed = GPIO_SPEED_LOW;
  HAL_GPIO_Init(GPIOD, &GPIO_InitStruct);

  /*Configure GPIO pin : CAM_RST_Pin */
  GPIO_InitStruct.Pin = CAM_RST_Pin;
  GPIO_InitStruct.Mode = GPIO_MODE_OUTPUT_PP;
  GPIO_InitStruct.Pull = GPIO_PULLDOWN;
  GPIO_InitStruct.Speed = GPIO_SPEED_LOW;
  HAL_GPIO_Init(CAM_RST_GPIO_Port, &GPIO_InitStruct);

  /*Configure GPIO pins : THRM_SEN_A_DRDY_Pin THRM_SEN_B_DRDY_Pin GPS_PIPPS_Pin */
  GPIO_InitStruct.Pin = THRM_SEN_A_DRDY_Pin|THRM_SEN_B_DRDY_Pin|GPS_PIPPS_Pin;
  GPIO_InitStruct.Mode = GPIO_MODE_IT_RISING;
  GPIO_InitStruct.Pull = GPIO_NOPULL;
  HAL_GPIO_Init(GPIOG, &GPIO_InitStruct);

  /*Configure GPIO pin : XCLK_Pin */
  GPIO_InitStruct.Pin = XCLK_Pin;
  GPIO_InitStruct.Mode = GPIO_MODE_AF_PP;
  GPIO_InitStruct.Pull = GPIO_NOPULL;
  GPIO_InitStruct.Speed = GPIO_SPEED_FAST;
  GPIO_InitStruct.Alternate = GPIO_AF0_MCO;
  HAL_GPIO_Init(XCLK_GPIO_Port, &GPIO_InitStruct);

  /*Configure GPIO pin : X_GPIO_1_Pin */
  GPIO_InitStruct.Pin = X_GPIO_1_Pin;
  GPIO_InitStruct.Mode = GPIO_MODE_OUTPUT_PP;
  GPIO_InitStruct.Pull = GPIO_PULLDOWN;
  GPIO_InitStruct.Speed = GPIO_SPEED_LOW;
  HAL_GPIO_Init(X_GPIO_1_GPIO_Port, &GPIO_InitStruct);

  /* EXTI interrupt init*/
  HAL_NVIC_SetPriority(EXTI1_IRQn, 0, 0);
  HAL_NVIC_EnableIRQ(EXTI1_IRQn);

  HAL_NVIC_SetPriority(EXTI2_IRQn, 0, 0);
  HAL_NVIC_EnableIRQ(EXTI2_IRQn);

  HAL_NVIC_SetPriority(EXTI15_10_IRQn, 0, 0);
  HAL_NVIC_EnableIRQ(EXTI15_10_IRQn);

}

/************************ (C) COPYRIGHT STMicroelectronics *****END OF FILE****/
